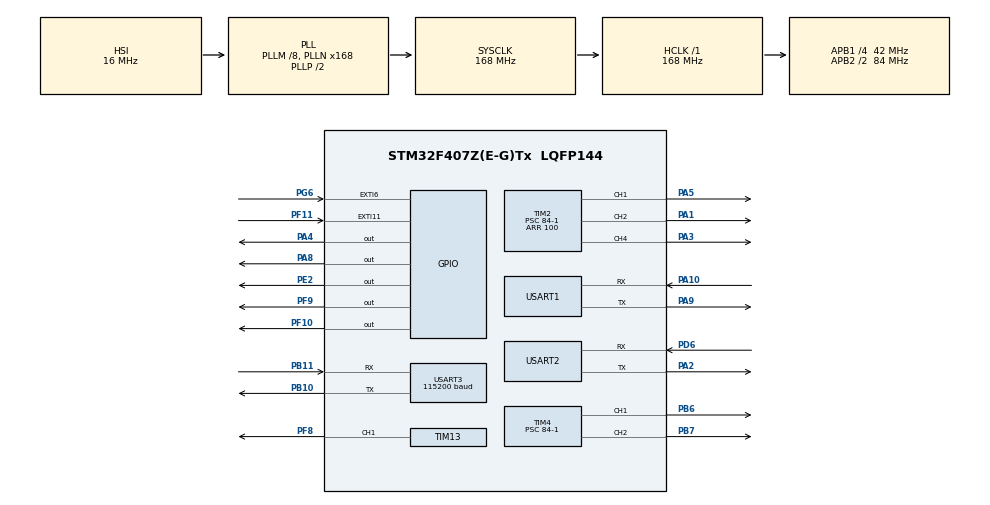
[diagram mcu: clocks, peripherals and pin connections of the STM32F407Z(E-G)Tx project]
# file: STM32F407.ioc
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Dma.Request0=USART2_TX
Dma.Request1=USART3_TX
Dma.USART2_TX.0.Direction=DMA_MEMORY_TO_PERIPH
Dma.USART2_TX.0.FIFOMode=DMA_FIFOMODE_DISABLE
Dma.USART2_TX.0.Instance=DMA1_Stream6
Dma.USART2_TX.0.MemDataAlignment=DMA_MDATAALIGN_BYTE
Dma.USART2_TX.0.MemInc=DMA_MINC_ENABLE
Dma.USART2_TX.0.Mode=DMA_NORMAL
Dma.USART2_TX.0.PeriphDataAlignment=DMA_PDATAALIGN_BYTE
Dma.USART2_TX.0.PeriphInc=DMA_PINC_DISABLE
Dma.USART2_TX.0.Priority=DMA_PRIORITY_LOW
Dma.USART3_TX.1.Direction=DMA_MEMORY_TO_PERIPH
Dma.USART3_TX.1.FIFOMode=DMA_FIFOMODE_DISABLE
Dma.USART3_TX.1.Instance=DMA1_Stream3
Dma.USART3_TX.1.MemDataAlignment=DMA_MDATAALIGN_BYTE
Dma.USART3_TX.1.MemInc=DMA_MINC_ENABLE
Dma.USART3_TX.1.Mode=DMA_NORMAL
Dma.USART3_TX.1.PeriphDataAlignment=DMA_PDATAALIGN_BYTE
Dma.USART3_TX.1.PeriphInc=DMA_PINC_DISABLE
Dma.USART3_TX.1.Priority=DMA_PRIORITY_LOW
Mcu.Family=STM32F4
Mcu.Name=STM32F407Z(E-G)Tx
Mcu.Package=LQFP144
NVIC.DMA1_Stream3_IRQn=true\:0\:0\:false\:false\:true\:false\:true\:true
NVIC.DMA1_Stream6_IRQn=true\:0\:0\:false\:false\:true\:false\:true\:true
NVIC.EXTI15_10_IRQn=true\:0\:0\:false\:false\:true\:true\:true\:true
NVIC.EXTI9_5_IRQn=true\:0\:0\:false\:false\:true\:true\:true\:true
NVIC.PriorityGroup=NVIC_PRIORITYGROUP_4
NVIC.TIM1_UP_TIM10_IRQn=true\:0\:0\:false\:false\:true\:true\:true\:true
NVIC.USART1_IRQn=true\:0\:0\:false\:false\:true\:true\:true\:true
NVIC.USART2_IRQn=true\:0\:0\:false\:false\:true\:true\:true\:true
NVIC.USART3_IRQn=true\:0\:0\:false\:false\:true\:true\:true\:true
PA1.Signal=S_TIM2_CH2
PA10.Mode=Asynchronous
PA10.Signal=USART1_RX
PA13.Mode=Serial_Wire
PA13.Signal=SYS_JTMS-SWDIO
PA14.Mode=Serial_Wire
PA14.Signal=SYS_JTCK-SWCLK
PA2.Mode=Asynchronous
PA2.Signal=USART2_TX
PA3.Signal=S_TIM2_CH4
PA4.Signal=GPIO_Output
PA5.Signal=S_TIM2_CH1_ETR
PA8.Signal=GPIO_Output
PA9.Mode=Asynchronous
PA9.Signal=USART1_TX
PB10.Mode=Asynchronous
PB10.Signal=USART3_TX
PB11.Mode=Asynchronous
PB11.Signal=USART3_RX
PB6.Signal=S_TIM4_CH1
PB7.Signal=S_TIM4_CH2
PC14-OSC32_IN.Mode=LSE-External-Oscillator
PC14-OSC32_IN.Signal=RCC_OSC32_IN
PC15-OSC32_OUT.Mode=LSE-External-Oscillator
PC15-OSC32_OUT.Signal=RCC_OSC32_OUT
PD6.Mode=Asynchronous
PD6.Signal=USART2_RX
PE2.PinState=GPIO_PIN_SET
PE2.Signal=GPIO_Output
PF10.Signal=GPIO_Output
PF11.GPIO_ModeDefaultEXTI=GPIO_MODE_IT_RISING_FALLING
PF11.Signal=GPXTI11
PF8.Signal=S_TIM13_CH1
PF9.PinState=GPIO_PIN_SET
PF9.Signal=GPIO_Output
PG6.GPIO_ModeDefaultEXTI=GPIO_MODE_IT_RISING_FALLING
PG6.Signal=GPXTI6
PH0-OSC_IN.Mode=HSE-External-Oscillator
PH0-OSC_IN.Signal=RCC_OSC_IN
PH1-OSC_OUT.Mode=HSE-External-Oscillator
PH1-OSC_OUT.Signal=RCC_OSC_OUT
ProjectManager.HeapSize=0x200
ProjectManager.StackSize=0x400
ProjectManager.TargetToolchain=MDK-ARM V5.32
RCC.48MHZClocksFreq_Value=84000000
RCC.AHBFreq_Value=168000000
RCC.APB1CLKDivider=RCC_HCLK_DIV4
RCC.APB1Freq_Value=42000000
RCC.APB1TimFreq_Value=84000000
RCC.APB2CLKDivider=RCC_HCLK_DIV2
RCC.APB2Freq_Value=84000000
RCC.APB2TimFreq_Value=168000000
RCC.CortexFreq_Value=168000000
RCC.HCLKFreq_Value=168000000
RCC.HSE_VALUE=25000000
RCC.HSI_VALUE=16000000
RCC.PLLM=8
RCC.PLLN=168
RCC.SYSCLKFreq_VALUE=168000000
RCC.SYSCLKSource=RCC_SYSCLKSOURCE_PLLCLK
RCC.VCOOutputFreq_Value=336000000
SH.S_TIM13_CH1.0=TIM13_CH1,PWM Generation1 CH1
SH.S_TIM2_CH1_ETR.0=TIM2_CH1,PWM Generation1 CH1
SH.S_TIM2_CH2.0=TIM2_CH2,PWM Generation2 CH2
SH.S_TIM2_CH4.0=TIM2_CH4,PWM Generation4 CH4
SH.S_TIM4_CH1.0=TIM4_CH1,PWM Generation1 CH1
SH.S_TIM4_CH2.0=TIM4_CH2,PWM Generation2 CH2
TIM1.Period=50000-1
TIM1.Prescaler=168-1
TIM13.Channel=TIM_CHANNEL_1
TIM13.OCPolarity_1=TIM_OCPOLARITY_LOW
TIM13.Period=100
TIM13.Prescaler=84-1
TIM13.Pulse=15
TIM2.Channel-PWM\ Generation1\ CH1=TIM_CHANNEL_1
TIM2.Channel-PWM\ Generation2\ CH2=TIM_CHANNEL_2
TIM2.Channel-PWM\ Generation4\ CH4=TIM_CHANNEL_4
TIM2.Period=100
TIM2.Prescaler=84-1
TIM4.Channel-PWM\ Generation1\ CH1=TIM_CHANNEL_1
TIM4.Channel-PWM\ Generation2\ CH2=TIM_CHANNEL_2
TIM4.Period=20000-1
TIM4.Prescaler=84-1
TIM8.Prescaler=168-1
USART1.VirtualMode=VM_ASYNC
USART2.VirtualMode=VM_ASYNC
USART3.BaudRate=115200
USART3.VirtualMode=VM_ASYNC
VP_TIM13_VS_ClockSourceINT.Mode=Enable_Timer
VP_TIM13_VS_OPM.Mode=OPM_bit
VP_TIM1_VS_ClockSourceINT.Mode=Internal
VP_TIM3_VS_ClockSourceINT.Mode=Internal
VP_TIM3_VS_ClockSourceITR.Mode=TriggerSource_ITR0
VP_TIM4_VS_ClockSourceINT.Mode=Internal
VP_TIM8_VS_ClockSourceINT.Mode=Internal
board=custom

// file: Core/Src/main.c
/* USER CODE BEGIN Header */
/**
  ******************************************************************************
  * @file           : main.c
  * @brief          : Main program body
  ******************************************************************************
  * @attention
  *
  * Copyright (c) 2025 STMicroelectronics.
  * All rights reserved.
  *
  * This software is licensed under terms that can be found in the LICENSE file
  * in the root directory of this software component.
  * If no LICENSE file comes with this software, it is provided AS-IS.
  *
  ******************************************************************************
  */
/* USER CODE END Header */
#include "main.h"
#include "dma.h"
#include "tim.h"
#include "usart.h"
#include "gpio.h"

/* USER CODE BEGIN Includes */
#include "ALLHeader.h"
#include "task_timer.h"
/* USER CODE END Includes */

void SystemClock_Config(void);

int main(void)
{

  /* MCU Configuration--------------------------------------------------------*/

  /* Reset of all peripherals, Initializes the Flash interface and the Systick. */
  HAL_Init();

  /* Configure the system clock */
  SystemClock_Config();

  /* Initialize all configured peripherals */
  MX_GPIO_Init();
  MX_DMA_Init();
  MX_USART2_UART_Init();
  MX_USART3_UART_Init();
  MX_TIM3_Init();
  MX_USART1_UART_Init();
  MX_TIM2_Init();
  MX_TIM4_Init();
  MX_TIM13_Init();
  MX_TIM8_Init();
  MX_TIM1_Init();
  /* USER CODE BEGIN 2 */
  motor_Init();
  usart_init();
	servo_init();
  HAL_TIM_Base_Start_IT(&htim8);
  HAL_TIM_Base_Start_IT(&htim1);

  HC_Start();

  // motor_Init();
  // motor_Speed_up(65);
  // motor_Speed_down(78);

  /* USER CODE END 2 */

  /* Infinite loop */
  while (1)
  {

    /* USER CODE BEGIN 3 */
    task_timer_process();

  }
  /* USER CODE END 3 */
}

void SystemClock_Config(void)
{
  RCC_OscInitTypeDef RCC_OscInitStruct = {0};
  RCC_ClkInitTypeDef RCC_ClkInitStruct = {0};

  /** Configure the main internal regulator output voltage
  */
  __HAL_RCC_PWR_CLK_ENABLE();
  __HAL_PWR_VOLTAGESCALING_CONFIG(PWR_REGULATOR_VOLTAGE_SCALE1);

  /** Initializes the RCC Oscillators according to the specified parameters
  * in the RCC_OscInitTypeDef structure.
  */
  RCC_OscInitStruct.OscillatorType = RCC_OSCILLATORTYPE_HSI;
  RCC_OscInitStruct.HSIState = RCC_HSI_ON;
  RCC_OscInitStruct.HSICalibrationValue = RCC_HSICALIBRATION_DEFAULT;
  RCC_OscInitStruct.PLL.PLLState = RCC_PLL_ON;
  RCC_OscInitStruct.PLL.PLLSource = RCC_PLLSOURCE_HSI;
  RCC_OscInitStruct.PLL.PLLM = 8;
  RCC_OscInitStruct.PLL.PLLN = 168;
  RCC_OscInitStruct.PLL.PLLP = RCC_PLLP_DIV2;
  RCC_OscInitStruct.PLL.PLLQ = 4;
  if (HAL_RCC_OscConfig(&RCC_OscInitStruct) != HAL_OK)
  {
    Error_Handler();
  }

  /** Initializes the CPU, AHB and APB buses clocks
  */
  RCC_ClkInitStruct.ClockType = RCC_CLOCKTYPE_HCLK|RCC_CLOCKTYPE_SYSCLK
                              |RCC_CLOCKTYPE_PCLK1|RCC_CLOCKTYPE_PCLK2;
  RCC_ClkInitStruct.SYSCLKSource = RCC_SYSCLKSOURCE_PLLCLK;
  RCC_ClkInitStruct.AHBCLKDivider = RCC_SYSCLK_DIV1;
  RCC_ClkInitStruct.APB1CLKDivider = RCC_HCLK_DIV4;
  RCC_ClkInitStruct.APB2CLKDivider = RCC_HCLK_DIV2;

  if (HAL_RCC_ClockConfig(&RCC_ClkInitStruct, FLASH_LATENCY_5) != HAL_OK)
  {
    Error_Handler();
  }
}

void Error_Handler(void)
{
  __disable_irq();
  while (1)
  {
  }
}
